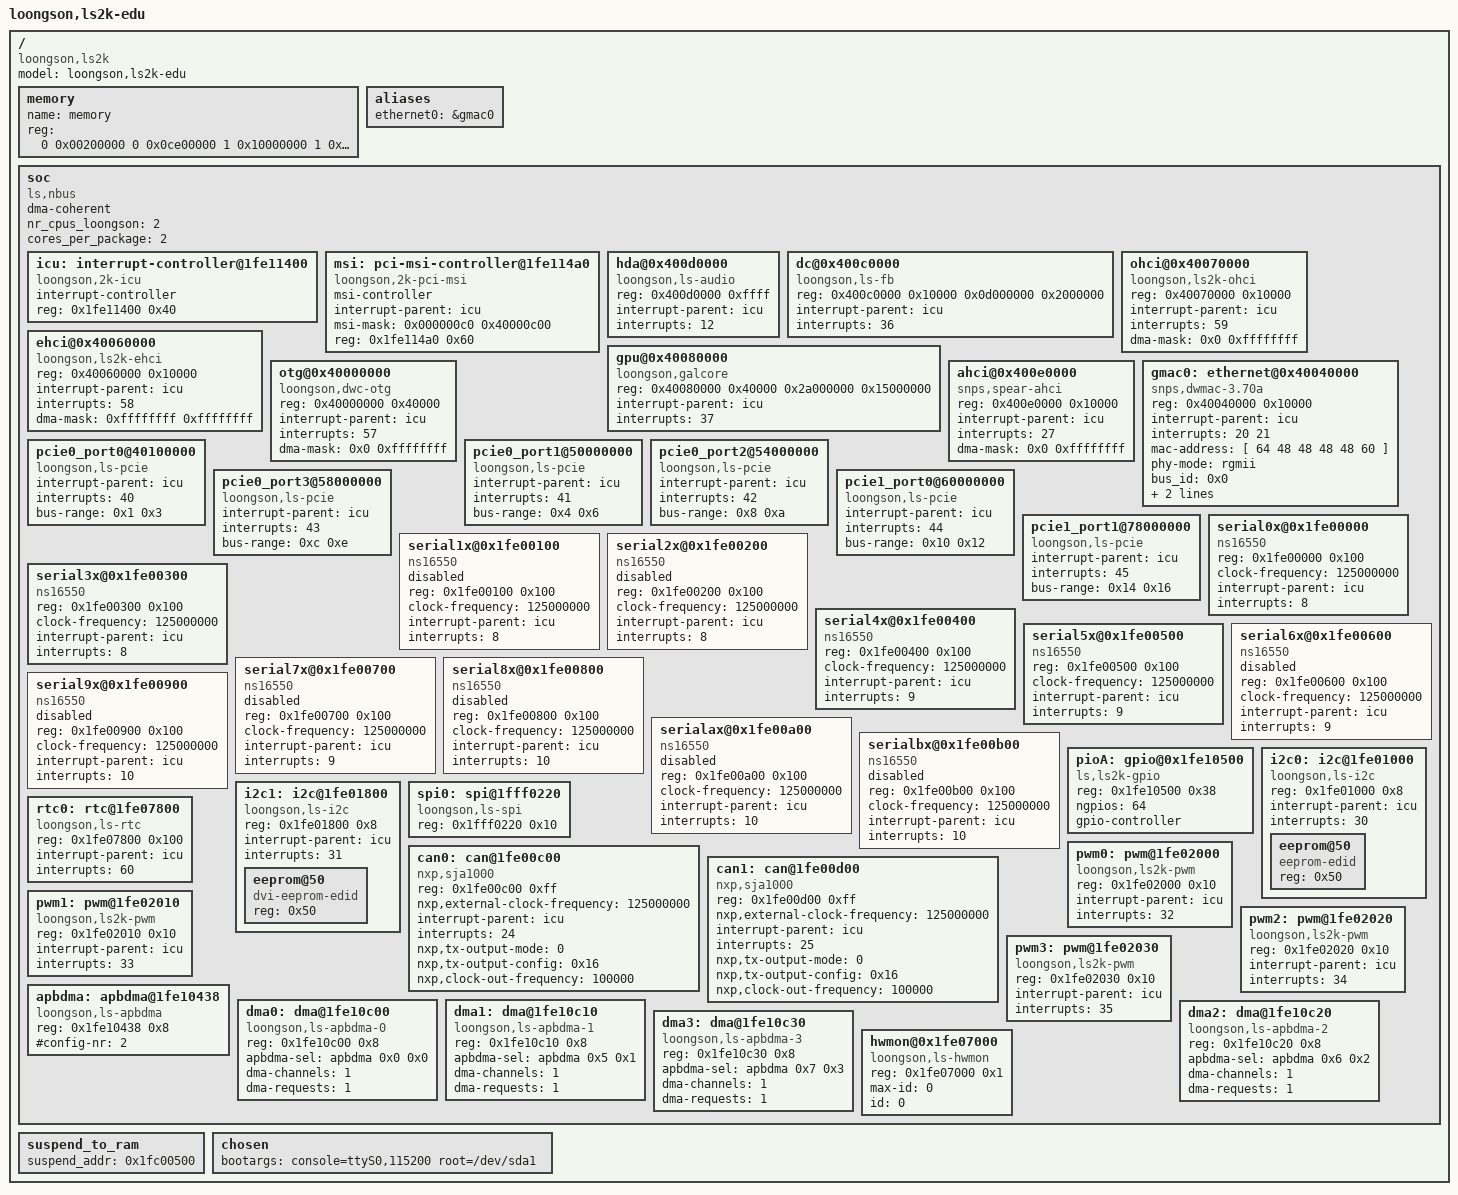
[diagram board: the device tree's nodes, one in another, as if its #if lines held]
/*
 * 2K1000 Device Tree Source for ls2k-edu
 */

/dts-v1/;
/ {
	model = "loongson,ls2k-edu";
	compatible = "loongson,ls2k";
	#address-cells = <2>;
	#size-cells = <2>;

	// Since 2K1000 support > 4GiB DIMM, use 2 cell for and address size
	memory {
		name = "memory";
		device_type = "memory";
#ifdef NOGPU
		reg =  <0 0x00200000 0 0x0ce00000	// 200MiB at 2MiB
#else
		reg =  <0 0x00200000 0 0x0ee00000	// 200MiB at 2MiB
#endif
			1 0x10000000 1 0xb0000000>;	// 7424 - 512 MiB at 4352MiB
	};

	aliases {
		ethernet0 = &gmac0;
	};

	// all soc device use 32bit address

	soc {
		compatible = "ls,nbus", "simple-bus";
		#address-cells = <1>;
		#size-cells = <1>;
		ranges = <0x10000000 0 0x10000000 0x10000000
			  0x40000000 0 0x40000000 0x40000000
			  0x20000000 0 0x20000000 0x20000000
              0x0d000000 0 0x0d000000 0x02000000>;

		dma-coherent;
		nr_cpus_loongson = <2>;
		cores_per_package = <2>;

		icu: interrupt-controller@1fe11400 {
			compatible = "loongson,2k-icu";
			interrupt-controller;
			#interrupt-cells = <1>;
			reg = <0x1fe11400 0x40>;
		};

		msi: pci-msi-controller@1fe114a0 {
			compatible = "loongson,2k-pci-msi";
			msi-controller;
			interrupt-parent = <&icu>;
			msi-mask = <0x000000c0 0x40000c00>;
			reg = <0x1fe114a0 0x60>;
		};

		/* HDA controller nodes:
		 * If you want to use the "hda" function,enable the "hda"
		 * controller by configure general configuration register 0.
		 */
		hda@0x400d0000 {
			compatible = "loongson,ls-audio";
			reg = <0x400d0000 0xffff>;
			interrupt-parent = <&icu>;
			interrupts = <12>;
		};

		dc@0x400c0000 {
			compatible = "loongson,ls-fb";
			reg = <0x400c0000 0x10000
#ifdef NOGPU
				   0x0d000000 0x2000000>;
#else
				   0x20000000 0x8000000>;
#endif
			interrupt-parent = <&icu>;
			interrupts = <36>;
		};

#ifndef NOGPU
		gpu@0x40080000 {
			compatible = "loongson,galcore";
			reg = <0x40080000 0x40000
				0x2a000000 0x15000000>;
			interrupt-parent = <&icu>;
			interrupts = <37>;
		};
#endif

		ohci@0x40070000 {
			compatible = "loongson,ls2k-ohci", "usb-ohci", "generic-ohci";
			reg = <0x40070000 0x10000>;
			interrupt-parent = <&icu>;
			interrupts = <59>;
			dma-mask = <0x0 0xffffffff>;
		};

		ehci@0x40060000 {
			compatible = "loongson,ls2k-ehci", "usb-ehci";
			reg = <0x40060000 0x10000>;
			interrupt-parent = <&icu>;
			interrupts = <58>;
			dma-mask = <0xffffffff 0xffffffff>;
		};

		otg@0x40000000 {
			compatible = "loongson,dwc-otg", "dwc-otg";
			reg = <0x40000000 0x40000>;
			interrupt-parent = <&icu>;
			interrupts = <57>;
			dma-mask = <0x0 0xffffffff>;
		};

		ahci@0x400e0000{
			compatible = "snps,spear-ahci";
			reg = <0x400e0000 0x10000>;
			interrupt-parent = <&icu>;
			interrupts = <27>;
			dma-mask = <0x0 0xffffffff>;
		};

		gmac0: ethernet@0x40040000 {
			compatible = "snps,dwmac-3.70a", "ls,ls-gmac";
			reg = <0x40040000 0x10000>;
			interrupt-parent = <&icu>;
			interrupts = <20 21>;
			interrupt-names = "macirq", "eth_wake_irq";
			mac-address = [ 64 48 48 48 48 60 ];/* [>mac 64:48:48:48:48:60 <]*/
			phy-mode = "rgmii";
			bus_id = <0x0>;
			phy_addr = <0xffffffff>;
			dma-mask = <0xffffffff 0xffffffff>;
		};

		pcie0_port0@40100000 {
			compatible = "loongson,ls-pcie";
			interrupt-parent = <&icu>;
			interrupts = <40>;
			#address-cells = <3>;
			#size-cells = <2>;
			bus-range = <0x1 0x3>;
			  ranges = <0x02000000 0x0 0x40100000 0x40100000 0x0 0x8000000  //mem
						0x01000000 0x0 0x18001000 0x18001000 0x0 0x0ff000>;  //io
		};

		pcie0_port1@50000000 {
			compatible = "loongson,ls-pcie";
			interrupt-parent = <&icu>;
			interrupts = <41>;
			#address-cells = <3>;
			#size-cells = <2>;
			bus-range = <0x4 0x6>;
			  ranges = <0x02000000 0x0 0x50000000 0x50000000 0x0 0x4000000  //mem
						0x01000000 0x0 0x18100000 0x18100000 0x0 0x100000>;  //io
		};

		pcie0_port2@54000000 {
			compatible = "loongson,ls-pcie";
			interrupt-parent = <&icu>;
			interrupts = <42>;
			#address-cells = <3>;
			#size-cells = <2>;
			bus-range = <0x8 0xa>;
			  ranges = <0x02000000 0x0 0x54000000 0x54000000 0x0 0x4000000  //mem
						0x01000000 0x0 0x18200000 0x18200000 0x0 0x100000>;  //io
		};

		pcie0_port3@58000000 {
			compatible = "loongson,ls-pcie";
			interrupt-parent = <&icu>;
			interrupts = <43>;
			#address-cells = <3>;
			#size-cells = <2>;
			bus-range = <0xc 0xe>;
			  ranges = <0x02000000 0x0 0x58000000 0x58000000 0x0 0x8000000  //mem
						0x01000000 0x0 0x18300000 0x18300000 0x0 0x100000>;  //io
		};

		pcie1_port0@60000000 {
			compatible = "loongson,ls-pcie";
			interrupt-parent = <&icu>;
			interrupts = <44>;
			#address-cells = <3>;
			#size-cells = <2>;
			bus-range = <0x10 0x12>;
			  ranges = <0x02000000 0x0 0x60000000 0x60000000 0x0 0x18000000  //mem
						0x01000000 0x0 0x18400000 0x18400000 0x0 0x100000>;  //io
		};

		pcie1_port1@78000000 {
			compatible = "loongson,ls-pcie";
			interrupt-parent = <&icu>;
			interrupts = <45>;
			#address-cells = <3>;
			#size-cells = <2>;
			bus-range = <0x14 0x16>;
			  ranges = <0x02000000 0x0 0x78000000 0x78000000 0x0 0x8000000  //mem
						0x01000000 0x0 0x18500000 0x18500000 0x0 0x100000>;  //io
		};

		serial0x@0x1fe00000{
			device_type = "serial";
			compatible = "ns16550";
			reg = <0x1fe00000 0x100>;
			clock-frequency = <125000000>;
			interrupt-parent = <&icu>;
			interrupts = <8>;
		};

		serial1x@0x1fe00100{
			device_type = "serial";
			compatible = "ns16550";
			reg = <0x1fe00100 0x100>;
			clock-frequency = <125000000>;
			interrupt-parent = <&icu>;
			interrupts = <8>;
			status = "disabled";
		};

		serial2x@0x1fe00200{
			device_type = "serial";
			compatible = "ns16550";
			reg = <0x1fe00200 0x100>;
			clock-frequency = <125000000>;
			interrupt-parent = <&icu>;
			interrupts = <8>;
			status = "disabled";
		};

		serial3x@0x1fe00300{
			device_type = "serial";
			compatible = "ns16550";
			reg = <0x1fe00300 0x100>;
			clock-frequency = <125000000>;
			interrupt-parent = <&icu>;
			interrupts = <8>;
			status = "okay";
		};

		serial4x@0x1fe00400{
			device_type = "serial";
			compatible = "ns16550";
			reg = <0x1fe00400 0x100>;
			clock-frequency = <125000000>;
			interrupt-parent = <&icu>;
			interrupts = <9>;
			status = "okay";
		};

		serial5x@0x1fe00500{
			device_type = "serial";
			compatible = "ns16550";
			reg = <0x1fe00500 0x100>;
			clock-frequency = <125000000>;
			interrupt-parent = <&icu>;
			interrupts = <9>;
			status = "okay";
		};

		serial6x@0x1fe00600{
			device_type = "serial";
			compatible = "ns16550";
			reg = <0x1fe00600 0x100>;
			clock-frequency = <125000000>;
			interrupt-parent = <&icu>;
			interrupts = <9>;
			status = "disabled";
		};

		serial7x@0x1fe00700{
			device_type = "serial";
			compatible = "ns16550";
			reg = <0x1fe00700 0x100>;
			clock-frequency = <125000000>;
			interrupt-parent = <&icu>;
			interrupts = <9>;
			status = "disabled";
		};

		serial8x@0x1fe00800{
			device_type = "serial";
			compatible = "ns16550";
			reg = <0x1fe00800 0x100>;
			clock-frequency = <125000000>;
			interrupt-parent = <&icu>;
			interrupts = <10>;
			status = "disabled";
		};

		serial9x@0x1fe00900{
			device_type = "serial";
			compatible = "ns16550";
			reg = <0x1fe00900 0x100>;
			clock-frequency = <125000000>;
			interrupt-parent = <&icu>;
			interrupts = <10>;
			status = "disabled";
		};

		serialax@0x1fe00a00{
			device_type = "serial";
			compatible = "ns16550";
			reg = <0x1fe00a00 0x100>;
			clock-frequency = <125000000>;
			interrupt-parent = <&icu>;
			interrupts = <10>;
			status = "disabled";
		};

		serialbx@0x1fe00b00{
			device_type = "serial";
			compatible = "ns16550";
			reg = <0x1fe00b00 0x100>;
			clock-frequency = <125000000>;
			interrupt-parent = <&icu>;
			interrupts = <10>;
			status = "disabled";
		};

		pioA:gpio@0x1fe10500{
			compatible = "ls,ls2k-gpio", "ls,ls-gpio";
			reg = <0x1fe10500 0x38>;
			ngpios = <64>;
			gpio-controller;
			#gpio-cells = <2>;
		};

		i2c0: i2c@1fe01000{
			compatible = "loongson,ls-i2c";
			reg = <0x1fe01000 0x8>;
			interrupt-parent = <&icu>;
			interrupts = <30>;
			#address-cells = <1>;
			#size-cells = <0>;

			/* DVO1's EDID, not really exist but Loongnix needs this */
			eeprom@50{
				compatible = "eeprom-edid";
				reg = <0x50>;
			};
		};

		i2c1: i2c@1fe01800{
			#address-cells = <1>;
			#size-cells = <0>;

			compatible = "loongson,ls-i2c";
			reg = <0x1fe01800 0x8>;
			interrupt-parent = <&icu>;
			interrupts = <31>;

			eeprom@50{
				compatible = "dvi-eeprom-edid";
				reg = <0x50>;
			};

		};

		spi0: spi@1fff0220{
			compatible = "loongson,ls-spi";
			#address-cells = <1>;
			#size-cells = <0>;
			reg = <0x1fff0220 0x10>;
		};

		rtc0: rtc@1fe07800{
			compatible = "loongson,ls-rtc";
			reg = <0x1fe07800 0x100>;
			interrupt-parent = <&icu>;
			interrupts = <60>;
		};

		/* CAN controller nodes:
		 * If you want to use the "can" function,enable the "can"
		 * controller by configure general configuration register 0.
		 */
		can0: can@1fe00c00{
			compatible = "nxp,sja1000";
			reg = <0x1fe00c00 0xff>;
			nxp,external-clock-frequency = <125000000>;
			interrupt-parent = <&icu>;
			interrupts = <24>;
			nxp,tx-output-mode = <0>;
			nxp,tx-output-config = <0x16>;
			nxp,clock-out-frequency = <100000>;
		};
		can1: can@1fe00d00{
			compatible = "nxp,sja1000";
			reg = <0x1fe00d00 0xff>;
			nxp,external-clock-frequency = <125000000>;
			interrupt-parent = <&icu>;
			interrupts = <25>;
			nxp,tx-output-mode = <0>;
			nxp,tx-output-config = <0x16>;
			nxp,clock-out-frequency = <100000>;
		};

		pwm0: pwm@1fe02000{
			compatible = "loongson,ls2k-pwm";
			reg = <0x1fe02000 0x10>;
			interrupt-parent = <&icu>;
			interrupts = <32>;
		};
		pwm1: pwm@1fe02010{
			compatible = "loongson,ls2k-pwm";
			reg = <0x1fe02010 0x10>;
			interrupt-parent = <&icu>;
			interrupts = <33>;
		};
		pwm2: pwm@1fe02020{
			compatible = "loongson,ls2k-pwm";
			reg = <0x1fe02020 0x10>;
			interrupt-parent = <&icu>;
			interrupts = <34>;
		};
		pwm3: pwm@1fe02030{
			compatible = "loongson,ls2k-pwm";
			reg = <0x1fe02030 0x10>;
			interrupt-parent = <&icu>;
			interrupts = <35>;
		};

		/* APB DMA controller nodes:
		 * apbdma node specify the commom property for dma node.
		 * the #config-nr must be 2,Used to provide APB sel region
		 * and APB DMA controler information.
		 */
		apbdma: apbdma@1fe10438{
			compatible = "loongson,ls-apbdma";
			reg = <0x1fe10438 0x8>;
			#config-nr = <2>;
		};
		/* DMA node should specify the apbdma-sel property using a
		 * phandle to the controller followed by number of APB sel
		 * region(max 9) and number of APB DMA controller(max 4).
		*/
		dma0: dma@1fe10c00 {
			compatible = "loongson,ls-apbdma-0";
			reg = <0x1fe10c00 0x8>;
			apbdma-sel = <&apbdma 0x0 0x0>;
			#dma-cells = <1>;
			dma-channels = <1>;
			dma-requests = <1>;
		};
		dma1: dma@1fe10c10 {
			compatible = "loongson,ls-apbdma-1";
			reg = <0x1fe10c10 0x8>;
			apbdma-sel = <&apbdma 0x5 0x1>;
			#dma-cells = <1>;
			dma-channels = <1>;
			dma-requests = <1>;
		};
		dma2: dma@1fe10c20 {
			compatible = "loongson,ls-apbdma-2";
			reg = <0x1fe10c20 0x8>;
			apbdma-sel = <&apbdma 0x6 0x2>;
			#dma-cells = <1>;
			dma-channels = <1>;
			dma-requests = <1>;
		};
		dma3: dma@1fe10c30 {
			compatible = "loongson,ls-apbdma-3";
			reg = <0x1fe10c30 0x8>;
			apbdma-sel = <&apbdma 0x7 0x3>;
			#dma-cells = <1>;
			dma-channels = <1>;
			dma-requests = <1>;
		};
		/*
		dma4: dma@1fe10c40 {
			compatible = "loongson,ls-apbdma-4";
			apbdma-sel = <&apbdma 0x0 0x0>;
			reg = <0x1fe10c40 0x8>;
			#dma-cells = <1>;
			dma-channels = <1>;
			dma-requests = <1>;
		};
		*/
		hwmon@0x1fe07000{
			#address-cells = <1>;
			#size-cells = <1>;

			compatible = "loongson,ls-hwmon";
			reg = <0x1fe07000 0x1>;
			max-id = <0>;
			id = <0>;
		};
	};

	suspend_to_ram {
		suspend_addr = <0x1fc00500>;
	};

	chosen {
		/* the redundant spaces are used for save new boot args */
		bootargs = "console=ttyS0,115200 root=/dev/sda1                                                                                                                                                                                                                                                                                                                                                                                                                                                                                                                      ";
	};
};
